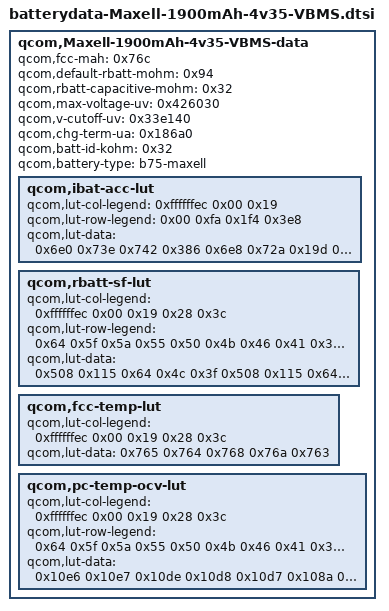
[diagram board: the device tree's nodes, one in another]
/* Copyright (c) 2018, The Linux Foundation. All rights reserved.
*  Copyright (c) 2018, Ketut P. Kumajaya.
*  Copyright (c) 2020, the_shahnawaz_sheikh (sheikhshahnawaz41299).
*
* This program is free software; you can redistribute it and/or modify
* it under the terms of the GNU General Public License version 2 and
* only version 2 as published by the Free Software Foundation.
*
* This program is distributed in the hope that it will be useful,
* but WITHOUT ANY WARRANTY; without even the implied warranty of
* MERCHANTABILITY or FITNESS FOR A PARTICULAR PURPOSE.  See the
* GNU General Public License for more details.
*/

qcom,Maxell-1900mAh-4v35-VBMS-data {
	qcom,fcc-mah = <0x76c>;
	qcom,default-rbatt-mohm = <0x94>;
	qcom,rbatt-capacitive-mohm = <0x32>;
	qcom,max-voltage-uv = <0x426030>;
	qcom,v-cutoff-uv = <0x33e140>;
	qcom,chg-term-ua = <0x186a0>;
	qcom,batt-id-kohm = <0x32>;
	qcom,battery-type = "b75-maxell";

	qcom,ibat-acc-lut {
		qcom,lut-col-legend = <0xffffffec 0x00 0x19>;
		qcom,lut-row-legend = <0x00 0xfa 0x1f4 0x3e8>;
		qcom,lut-data = <0x6e0 0x73e 0x742 0x386 0x6e8 0x72a 0x19d 0x640 0x721 0x1c 0x46f 0x6ea>;
	};

	qcom,rbatt-sf-lut {
		qcom,lut-col-legend = <0xffffffec 0x00 0x19 0x28 0x3c>;
		qcom,lut-row-legend = <0x64 0x5f 0x5a 0x55 0x50 0x4b 0x46 0x41 0x3c 0x37 0x32 0x2d 0x28 0x23 0x1e 0x19 0x14 0x10 0x0d 0x0b 0x0a 0x09 0x08 0x07 0x06 0x05 0x04 0x03 0x02 0x01>;
		qcom,lut-data = <0x508 0x115 0x64 0x4c 0x3f 0x508 0x115 0x64 0x4c 0x3f 0x4c9 0x124 0x69 0x4f 0x41 0x484 0x12b 0x6d 0x52 0x43 0x45f 0x12a 0x74 0x55 0x45 0x43d 0x11e 0x7a 0x59 0x49 0x442 0x111 0x83 0x5e 0x4b 0x44e 0x10c 0x8c 0x66 0x50 0x45f 0x108 0x77 0x6d 0x58 0x474 0x107 0x64 0x4d 0x42 0x493 0x109 0x64 0x4e 0x43 0x4cb 0x10b 0x65 0x51 0x46 0x51e 0x10e 0x69 0x55 0x4b 0x591 0x113 0x6d 0x56 0x4f 0x62c 0x11c 0x6d 0x56 0x46 0x6fb 0x125 0x6a 0x50 0x45 0x931 0x125 0x69 0x4f 0x43 0xc76 0x13d 0x67 0x4e 0x42 0x116b 0x16d 0x62 0x4c 0x43 0x15ab 0x19d 0x66 0x50 0x45 0x1134 0x19b 0x67 0x51 0x46 0x1270 0x1aa 0x6a 0x53 0x47 0x1f7b 0x1da 0x6f 0x57 0x49 0x400b 0x219 0x72 0x58 0x49 0x7daf 0x26c 0x74 0x55 0x47 0xcdbe 0x2dd 0x70 0x53 0x47 0x11d46 0x37b 0x71 0x57 0x4b 0x16a95 0x436 0x7b 0x62 0x53 0x1c72e 0x53b 0x96 0x77 0x5f 0x2863b 0xabf 0xe5 0xb6 0x142>;
	};

	qcom,fcc-temp-lut {
		qcom,lut-col-legend = <0xffffffec 0x00 0x19 0x28 0x3c>;
		qcom,lut-data = <0x765 0x764 0x768 0x76a 0x763>;
	};

	qcom,pc-temp-ocv-lut {
		qcom,lut-col-legend = <0xffffffec 0x00 0x19 0x28 0x3c>;
		qcom,lut-row-legend = <0x64 0x5f 0x5a 0x55 0x50 0x4b 0x46 0x41 0x3c 0x37 0x32 0x2d 0x28 0x23 0x1e 0x19 0x14 0x10 0x0d 0x0b 0x0a 0x09 0x08 0x07 0x06 0x05 0x04 0x03 0x02 0x01 0x00>;
		qcom,lut-data = <0x10e6 0x10e7 0x10de 0x10d8 0x10d7 0x108a 0x109f 0x10a1 0x109e 0x109c 0x103c 0x1062 0x1069 0x1068 0x1065 0xff5 0x1029 0x1033 0x1032 0x1030 0xfbb 0xff1 0x1000 0xfff 0xffd 0xf7b 0xfb8 0xfd1 0xfd0 0xfce 0xf4e 0xf80 0xfa4 0xfa4 0xfa3 0xf26 0xf56 0xf7c 0xf7d 0xf7b 0xf04 0xf31 0xf48 0xf54 0xf56 0xee7 0xf12 0xf1d 0xf1e 0xf1f 0xed0 0xef7 0xf01 0xf03 0xf04 0xebf 0xee1 0xeea 0xeec 0xeed 0xeb0 0xece 0xed8 0xeda 0xeda 0xea1 0xebf 0xec9 0xec9 0xecb 0xe92 0xeb5 0xebd 0xebb 0xeb3 0xe7c 0xea7 0xeaf 0xea8 0xe9c 0xe5e 0xe8d 0xe99 0xe93 0xe86 0xe36 0xe7c 0xe7a 0xe73 0xe67 0xe07 0xe71 0xe69 0xe62 0xe59 0xddc 0xe6b 0xe66 0xe60 0xe55 0xdbf 0xe67 0xe65 0xe5f 0xe54 0xd9e 0xe63 0xe64 0xe5e 0xe53 0xd7b 0xe5e 0xe62 0xe5d 0xe51 0xd54 0xe56 0xe5f 0xe58 0xe4b 0xd2d 0xe47 0xe54 0xe4a 0xe39 0xd05 0xe2d 0xe36 0xe25 0xe14 0xcdd 0xe06 0xe03 0xdef 0xde0 0xcb8 0xdcd 0xdc0 0xdab 0xd9c 0xc94 0xd75 0xd66 0xd4e 0xd3c 0xc6b 0xcf0 0xcd4 0xcaa 0xc9c 0xbb8 0xbb8 0xbb8 0xbb8 0xbb8>;
	};
};
